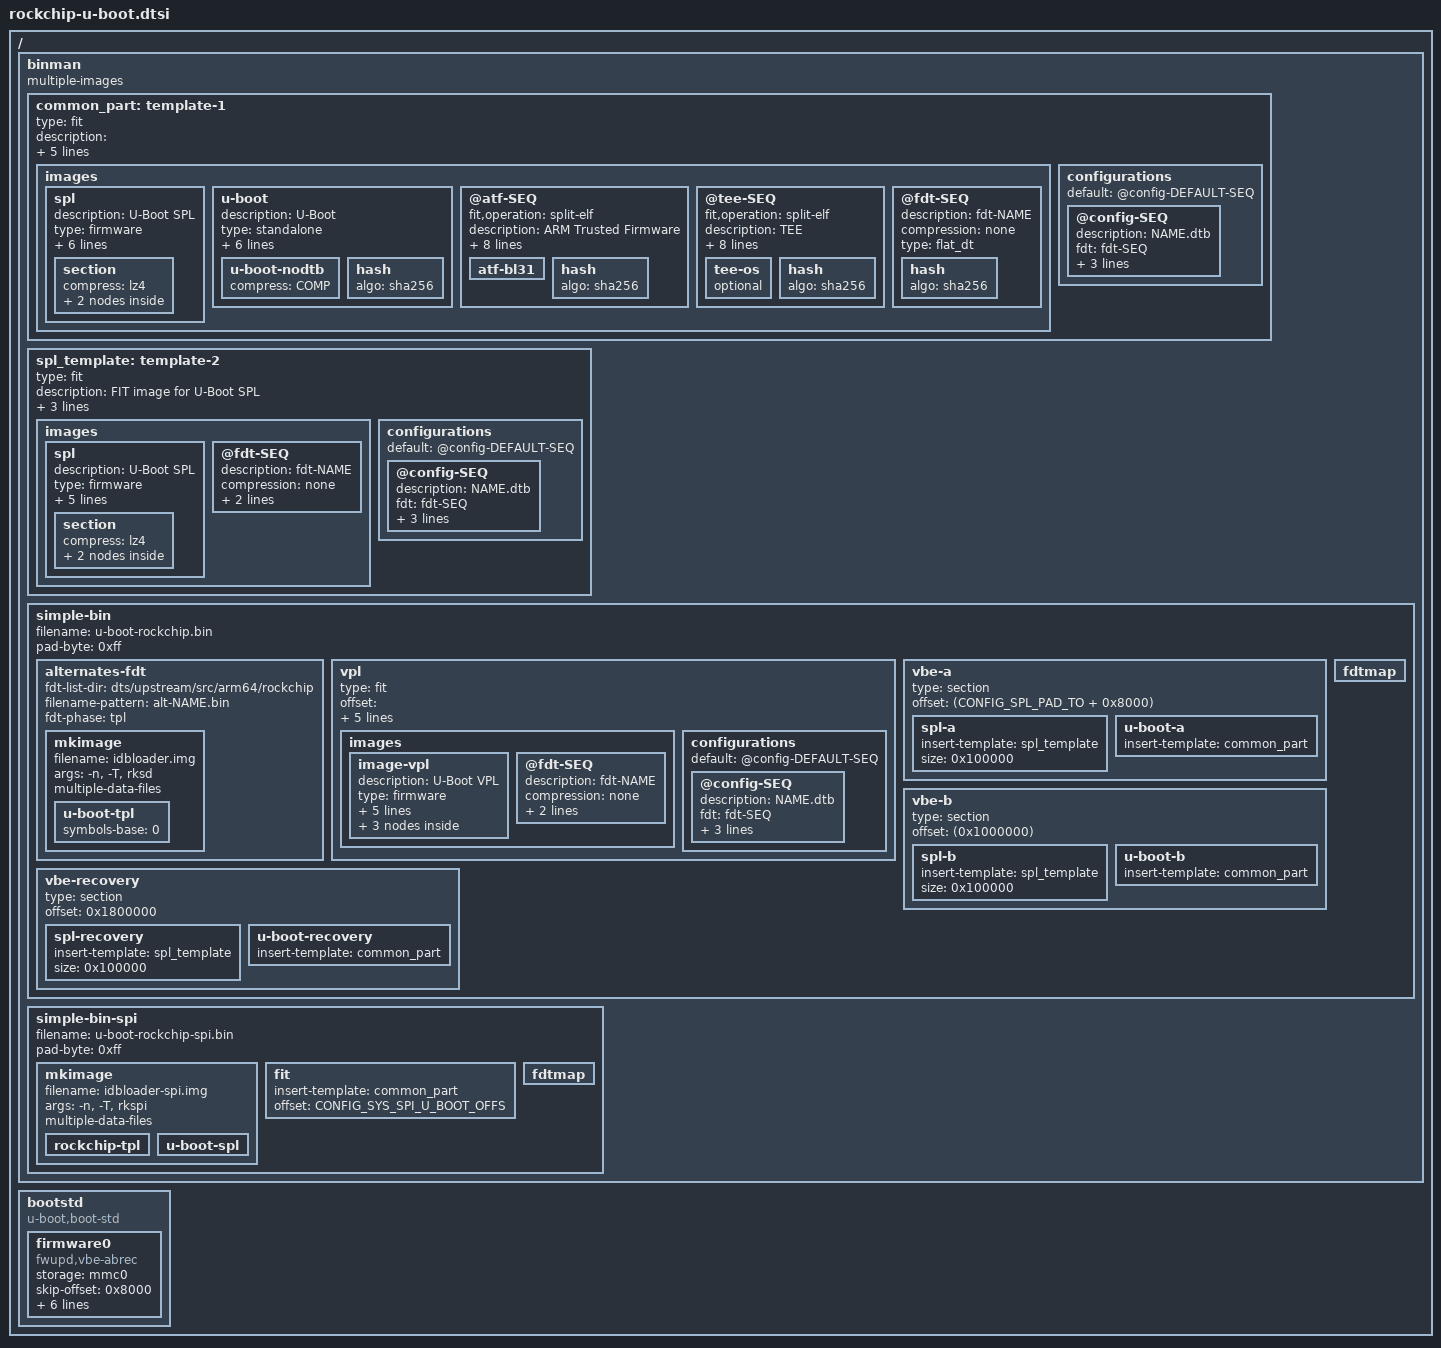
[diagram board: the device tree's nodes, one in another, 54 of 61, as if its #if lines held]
// SPDX-License-Identifier: GPL-2.0+
/*
 * Copyright (C) 2019 Jagan Teki <jagan@amarulasolutions.com>
 */

#include <config.h>

#ifdef CONFIG_ARM64
#define ARCH	"arm64"
#else
#define ARCH	"arm"
#endif

#if defined(CONFIG_SPL_GZIP)
#define COMP	"gzip"
#elif defined(CONFIG_SPL_LZMA)
#define COMP	"lzma"
#else
#define COMP	"none"
#endif

#if defined(CONFIG_SPL_FIT) && (defined(CONFIG_ARM64) || defined(CONFIG_SPL_OPTEE_IMAGE))
#define HAS_FIT
#endif

/ {
	binman: binman {
		multiple-images;
	};

#ifdef CONFIG_VPL
	bootstd {
		bootph-verify;
		compatible = "u-boot,boot-std";

		/*
		 * This is used for the VBE OS-request tests. A FAT filesystem
		 * created in a partition with the VBE information appearing
		 * before the partition starts.
		 *
		 * Offsets are aligned to the media block-size, typically 0x200
		 */
		firmware0 {
			bootph-verify;
			compatible = "fwupd,vbe-abrec";
			storage = "mmc0";
			skip-offset = <0x8000>;
			area-start = <CONFIG_SPL_PAD_TO>;
			area-size = <0x800000>;
			state-offset = <(CONFIG_SPL_PAD_TO - 0x400)>;
			state-size = <0x40>;
			version-offset = <(CONFIG_SPL_PAD_TO - 0x200)>;
			version-size = <0x100>;
		};
	};
#endif
};

#ifdef CONFIG_SPL
&binman {
#ifdef HAS_FIT
	common_part: template-1 {
		type = "fit";
#ifdef CONFIG_ARM64
		description = "FIT image for U-Boot with bl31 (TF-A)";
#else
		description = "FIT image with OP-TEE";
#endif
		#address-cells = <1>;
		fit,fdt-list = "of-list";
		fit,external-offset = <CONFIG_FIT_EXTERNAL_OFFSET>;
		fit,align = <512>;
		images {
#ifdef CONFIG_VPL
			spl {
				description = "U-Boot SPL";
				type = "firmware";
				os = "u-boot";
				arch = ARCH;
				compression = "lz4";
				load = <CONFIG_SPL_TEXT_BASE>;
				entry = <CONFIG_SPL_TEXT_BASE>;
				phase = "spl";
				section {
					compress = "lz4";
					u-boot-spl-nodtb {
					};
					u-boot-spl-bss-pad {
					};
				};
			};
#endif /* VPL */
			u-boot {
				description = "U-Boot";
				type = "standalone";
				os = "u-boot";
				arch = ARCH;
				compression = COMP;
				load = <CONFIG_TEXT_BASE>;
				entry = <CONFIG_TEXT_BASE>;
				phase = "u-boot";
				u-boot-nodtb {
					compress = COMP;
				};
#ifdef CONFIG_SPL_FIT_SIGNATURE
				hash {
					algo = "sha256";
				};
#endif
			};

#ifdef CONFIG_ARM64
			@atf-SEQ {
				fit,operation = "split-elf";
				description = "ARM Trusted Firmware";
				type = "firmware";
				arch = ARCH;
				os = "arm-trusted-firmware";
				compression = "none";
				phase = "u-boot";
				fit,load;
				fit,entry;
				fit,data;

				atf-bl31 {
				};
#ifdef CONFIG_SPL_FIT_SIGNATURE
				hash {
					algo = "sha256";
				};
#endif
			};
			@tee-SEQ {
				fit,operation = "split-elf";
				description = "TEE";
				type = "tee";
				arch = ARCH;
				os = "tee";
				compression = "none";
				phase = "u-boot";
				fit,load;
				fit,entry;
				fit,data;

				tee-os {
					optional;
				};
#ifdef CONFIG_SPL_FIT_SIGNATURE
				hash {
					algo = "sha256";
				};
#endif
			};
#else /* !CONFIG_ARM64 */
			op-tee {
				description = "OP-TEE";
				type = "tee";
				arch = ARCH;
				os = "tee";
				compression = "none";
				load = <(CFG_SYS_SDRAM_BASE + 0x8400000)>;
				entry = <(CFG_SYS_SDRAM_BASE + 0x8400000)>;
				phase = "u-boot";

				tee-os {
				};
#ifdef CONFIG_SPL_FIT_SIGNATURE
				hash {
					algo = "sha256";
				};
#endif
			};
#endif /* CONFIG_ARM64 */

			@fdt-SEQ {
				description = "fdt-NAME";
				compression = "none";
				type = "flat_dt";
#ifdef CONFIG_SPL_FIT_SIGNATURE
				hash {
					algo = "sha256";
				};
#endif
			};
		};

		configurations {
			default = "@config-DEFAULT-SEQ";
			@config-SEQ {
				description = "NAME.dtb";
				fdt = "fdt-SEQ";
#ifdef CONFIG_ARM64
# ifdef CONFIG_VPL
				fit,firmware = "atf-1", "u-boot", "spl";
# else
				fit,firmware = "atf-1", "u-boot";
# endif
#else
				fit,firmware = "op-tee", "u-boot";
#endif
				fit,loadables;
				fit,compatible;
			};
		};
	};

	spl_template: template-2 {
		type = "fit";
		description = "FIT image for U-Boot SPL";
		#address-cells = <1>;
		fit,fdt-list = "of-list";
		fit,align = <512>;
		fit,external-offset = <0>;
		images {
			spl {
				description = "U-Boot SPL";
				type = "firmware";
				os = "u-boot";
				arch = ARCH;
				compression = "lz4";
				load = <CONFIG_SPL_TEXT_BASE>;
				entry = <CONFIG_SPL_TEXT_BASE>;
				section {
					compress = "lz4";
					u-boot-spl-nodtb {
					};
					u-boot-spl-bss-pad {
					};
				};
			};
			@fdt-SEQ {
				description = "fdt-NAME";
				compression = "none";
				type = "flat_dt";
				fit,fdt-phase = "spl";
			};
		};
		configurations {
			default = "@config-DEFAULT-SEQ";
			@config-SEQ {
				description = "NAME.dtb";
				fdt = "fdt-SEQ";
				fit,firmware = "spl";
				fit,loadables;
				fit,compatible;
			};
		};
	};
#endif /* HAS_FIT */

	simple-bin {
		filename = "u-boot-rockchip.bin";
		pad-byte = <0xff>;

#ifdef CONFIG_VPL
		alternates-fdt {
			fdt-list-dir = "dts/upstream/src/arm64/rockchip";
			filename-pattern = "alt-NAME.bin";
			fdt-phase = "tpl";

			mkimage {
				filename = "idbloader.img";
				args = "-n", CONFIG_SYS_SOC, "-T", "rksd";
				multiple-data-files;

				u-boot-tpl {
					symbols-base = <0>;
				};
			};
		};

		vpl {
			type = "fit";
			offset = <(CONFIG_SYS_MMCSD_RAW_MODE_U_BOOT_SECTOR * 0x200 + 0x8000)>;
			description = "FIT image for U-Boot TPL";
			#address-cells = <1>;
			fit,fdt-list = "of-list";
			fit,align = <512>;
			fit,external-offset = <0>;
			images {
				image-vpl {
					description = "U-Boot VPL";
					type = "firmware";
					os = "u-boot";
					arch = ARCH;
					compression = "lz4";
					load = <CONFIG_VPL_TEXT_BASE>;
					entry = <CONFIG_VPL_TEXT_BASE>;
					section {
						compress = "lz4";
						u-boot-vpl-nodtb {
							symbols-base = <0>;
						};
						u-boot-vpl-bss-pad {
						};
					};
				};
				@fdt-SEQ {
					description = "fdt-NAME";
					compression = "none";
					type = "flat_dt";
					fit,fdt-phase = "vpl";
				};
			};
			configurations {
				default = "@config-DEFAULT-SEQ";
				@config-SEQ {
					description = "NAME.dtb";
					fdt = "fdt-SEQ";
					fit,firmware = "image-vpl";
					fit,loadables;
					fit,compatible;
				};
			};
		};
# ifdef CONFIG_BOOTMETH_VBE_ABREC
		vbe-a {
			type = "section";
			offset = <(CONFIG_SPL_PAD_TO + 0x8000)>;
			spl-a {
				insert-template = <&spl_template>;
				size = <0x100000>;
			};

			u-boot-a {
				insert-template = <&common_part>;
			};
		};
		vbe-b {
			type = "section";
			offset = <(0x1000000)>;
			spl-b {
				insert-template = <&spl_template>;
				size = <0x100000>;
			};

			u-boot-b {
				insert-template = <&common_part>;
			};
		};
		vbe-recovery {
			type = "section";
			offset = <0x1800000>;
			spl-recovery {
				insert-template = <&spl_template>;
				size = <0x100000>;
			};

			u-boot-recovery {
				insert-template = <&common_part>;
			};
		};
# else /* CONFIG_BOOTMETH_VBE_SIMPLE */
		vbe {
			type = "fit";
			offset = <(CONFIG_SPL_PAD_TO + 0x8000)>;
			insert-template = <&common_part>;
		};
# endif /* VBE method */
#else /* !VPL */

		mkimage {
			filename = "idbloader.img";
			args = "-n", CONFIG_SYS_SOC, "-T", "rksd";
			multiple-data-files;

#ifdef CONFIG_ROCKCHIP_EXTERNAL_TPL
			rockchip-tpl {
			};
#elif defined(CONFIG_TPL)
			u-boot-tpl {
			};
#endif
			u-boot-spl {
			};
		};

#ifdef HAS_FIT
		fit {
			offset = <CONFIG_SPL_PAD_TO>;
			insert-template = <&common_part>;
		};
#else
		u-boot-img {
			offset = <CONFIG_SPL_PAD_TO>;
		};
#endif /* HAS_FIT */
#endif /* VPL */
		fdtmap {
		};
	};

#ifdef CONFIG_ROCKCHIP_SPI_IMAGE
	simple-bin-spi {
		filename = "u-boot-rockchip-spi.bin";
		pad-byte = <0xff>;

		mkimage {
			filename = "idbloader-spi.img";
			args = "-n", CONFIG_SYS_SOC, "-T", "rkspi";
			multiple-data-files;

#ifdef CONFIG_ROCKCHIP_EXTERNAL_TPL
			rockchip-tpl {
			};
#elif defined(CONFIG_TPL)
			u-boot-tpl {
			};
#endif
			u-boot-spl {
			};
		};

#if defined(CONFIG_ARM64) || defined(CONFIG_SPL_OPTEE_IMAGE)
		fit {
			insert-template = <&common_part>;
#else
		u-boot-img {
#endif
			/* Sync with u-boot,spl-payload-offset if present */
			offset = <CONFIG_SYS_SPI_U_BOOT_OFFS>;
		};
		fdtmap {
		};
	};
#endif /* CONFIG_ROCKCHIP_SPI_IMAGE */
};
#endif /* CONFIG_SPL */
